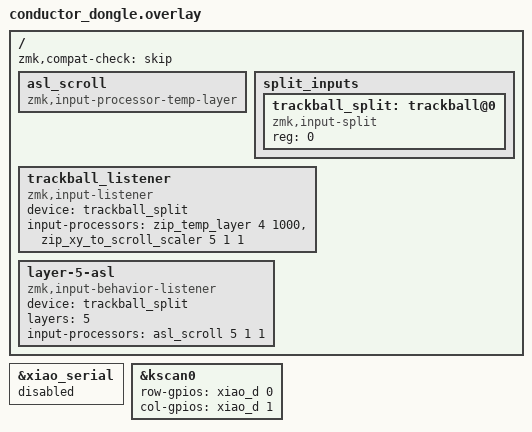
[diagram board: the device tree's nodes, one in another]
/ { zmk,compat-check = "skip"; };

#include "monokey.dtsi"
#include <input/processors.dtsi>

/ {
    asl_scroll: asl_scroll {
        compatible = "zmk,input-processor-temp-layer";
        #input-processor-cells = <3>;
    };
};

&xiao_serial { status = "disabled"; };

&kscan0 {
    row-gpios = <&xiao_d 0 (GPIO_ACTIVE_HIGH | GPIO_PULL_DOWN)>;
    col-gpios = <&xiao_d 1 GPIO_ACTIVE_HIGH>;
};

/ {

    split_inputs {
        #address-cells = <1>;
        #size-cells = <0>;

        trackball_split: trackball@0 {
            compatible = "zmk,input-split";
            reg = <0>;
            /* ※ドングルには物理センサーが付いていないので、device = <&trackball>; は書きません */
        };
    };

    trackball_listener {
        compatible = "zmk,input-listener";
        device = <&trackball_split>;

        input-processors = 
            <&zip_temp_layer 4 1000>,
            <&zip_xy_to_scroll_scaler 5 1 1>;

    };

    layer-5-asl {
        compatible = "zmk,input-behavior-listener";
        device = <&trackball_split>;
        layers = <5>;
        input-processors = <&asl_scroll 5 1 1>;
    };

};
